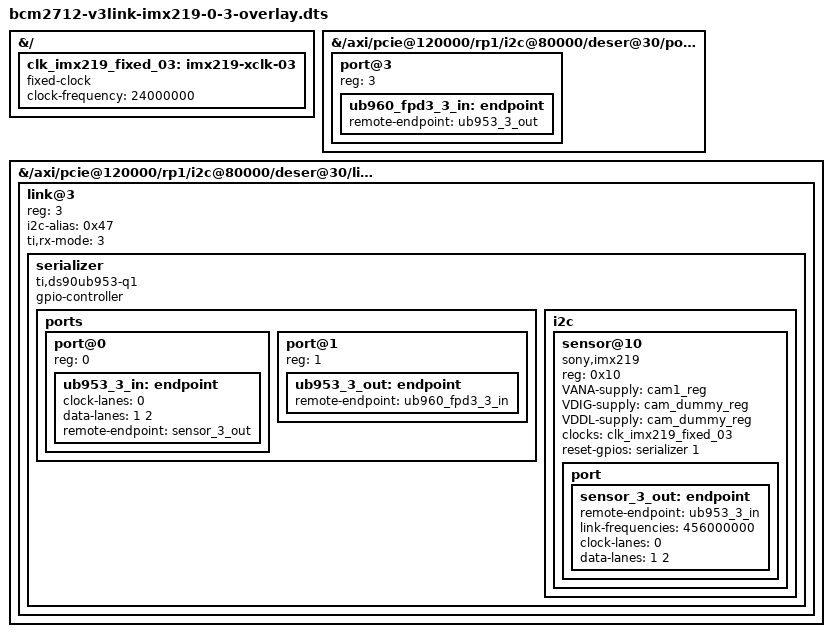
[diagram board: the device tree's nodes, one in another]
// SPDX-License-Identifier: GPL-2.0
/*
 * IMX219 Camera Module for V3-Link d-ch Adapter Board
 * https://docs.arducam.com/V3Link-Camera-Solution/V3Link-Camera-Solution-on-TI-Platform/Introduction/
 *
 * Copyright (c) 2024 Texas Instruments Incorporated - http://www.ti.com/
 */

/dts-v1/;
/plugin/;

#include <dt-bindings/gpio/gpio.h>

&{/} {
	clk_imx219_fixed_03: imx219-xclk-03 {
		compatible = "fixed-clock";
		#clock-cells = <0>;
		clock-frequency = <24000000>;
	};
};

&{/axi/pcie@120000/rp1/i2c@80000/deser@30/ports} {
	#address-cells = <1>;
	#size-cells = <0>;

	/* FPDLink RX 3 */
	port@3 {
		reg = <3>;

		ub960_fpd3_3_in: endpoint {
			remote-endpoint = <&ub953_3_out>;
		};
	};
};

&{/axi/pcie@120000/rp1/i2c@80000/deser@30/links} {
	#address-cells = <1>;
	#size-cells = <0>;

	link@3 {
		reg = <3>;
		i2c-alias = <0x47>;

		ti,rx-mode = <3>;

		serializer: serializer {
			compatible = "ti,ds90ub953-q1";
			gpio-controller;
			#gpio-cells = <2>;

			#clock-cells = <0>;

			ports {
				#address-cells = <1>;
				#size-cells = <0>;

				port@0 {
					reg = <0>;
					ub953_3_in: endpoint {
						clock-lanes = <0>;
						data-lanes = <1 2>;
						remote-endpoint = <&sensor_3_out>;
					};
				};

				port@1 {
					reg = <1>;

					ub953_3_out: endpoint {
						remote-endpoint = <&ub960_fpd3_3_in>;
					};
				};
			};

			i2c {
				#address-cells = <1>;
				#size-cells = <0>;

				sensor@10 {
					compatible = "sony,imx219";
					reg = <0x10>;
					VANA-supply = <&cam1_reg>;	/* 2.8v */
					VDIG-supply = <&cam_dummy_reg>;	/* 1.8v */
					VDDL-supply = <&cam_dummy_reg>;	/* 1.2v */
					clocks = <&clk_imx219_fixed_03>;
					clock-names = "xclk";
					reset-gpios = <&serializer 1 GPIO_ACTIVE_HIGH>;

					port {
						sensor_3_out: endpoint {
							remote-endpoint = <&ub953_3_in>;
							link-frequencies = /bits/ 64 <456000000>;
							clock-lanes = <0>;
							data-lanes = <1 2>;
						};
					};
				};
			};
		};
	};
};
